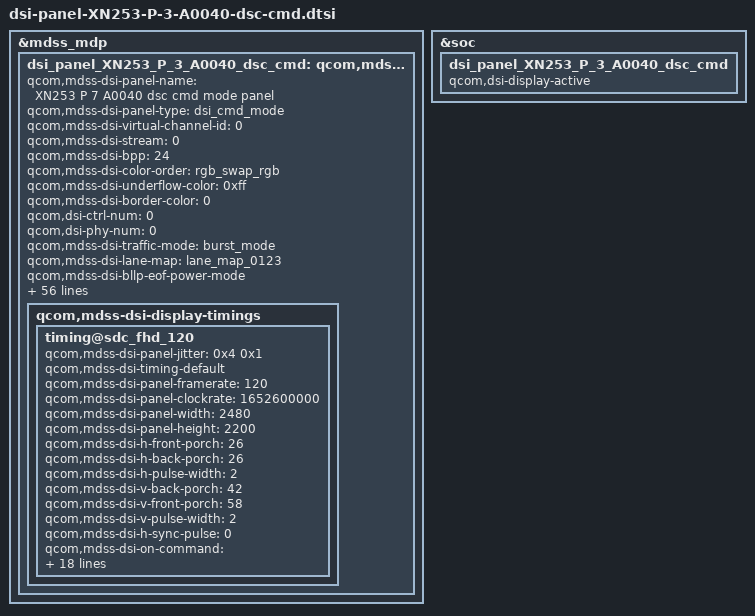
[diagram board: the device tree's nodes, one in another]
&mdss_mdp {
	dsi_panel_XN253_P_3_A0040_dsc_cmd: qcom,mdss_dsi_panel_XN253_P_3_A0040_dsc_cmd {
		qcom,mdss-dsi-panel-name = "XN253 P 7 A0040 dsc cmd mode panel";
		qcom,mdss-dsi-panel-type = "dsi_cmd_mode";
		qcom,mdss-dsi-virtual-channel-id = <0>;
		qcom,mdss-dsi-stream = <0>;
		qcom,mdss-dsi-bpp = <24>;
		qcom,mdss-dsi-color-order = "rgb_swap_rgb";
		qcom,mdss-dsi-underflow-color = <0xff>;
		qcom,mdss-dsi-border-color = <0>;
		qcom,dsi-ctrl-num = <0>;
		qcom,dsi-phy-num = <0>;
		qcom,mdss-dsi-traffic-mode = "burst_mode";
		qcom,mdss-dsi-lane-map = "lane_map_0123";
		qcom,mdss-dsi-bllp-eof-power-mode;
		qcom,mdss-dsi-bllp-power-mode;
		qcom,mdss-dsi-lane-0-state;
		qcom,mdss-dsi-lane-1-state;
		qcom,mdss-dsi-lane-2-state;
		qcom,mdss-dsi-lane-3-state;
		qcom,mdss-dsi-dma-trigger = "trigger_sw";
		qcom,mdss-dsi-dma-schedule-line = <1>;
		qcom,mdss-dsi-dma-schedule-window = <10>;
		qcom,mdss-dsi-mdp-trigger = "none";
		qcom,mdss-dsi-reset-sequence = <1 2>, <0 5>, <1 25>;
		qcom,mdss-dsi-te-pin-select = <1>;
		qcom,mdss-dsi-te-dcs-command = <1>;
		qcom,mdss-pan-physical-width-dimension = <71>;
		qcom,mdss-pan-physical-height-dimension = <157>;
		qcom,mdss-dsi-init-delay-us = <1000>;
		qcom,mdss-dsi-te-check-enable;
		qcom,mdss-dsi-te-using-te-pin;
		qcom,mdss-dsi-lp11-init;
		qcom,mdss-dsi-wr-mem-start = <0x2c>;
		qcom,mdss-dsi-wr-mem-continue = <0x3c>;
		qcom,mdss-dsi-panel-jitter = <0x4 0x1>;
		qcom,mdss-bl-high2bit;
		/* HDR Setting */
		qcom,mdss-dsi-panel-hdr-enabled;
		qcom,mdss-dsi-panel-hdr-color-primaries = <15635 16450 34000 16000 13250 34500 7500 3000>;
		//update for [MPC15]android.mediapc.cts.PerformanceClassTest#testDisplayHdr pass
		//qcom,mdss-dsi-panel-peak-brightness = <5400000>;
		qcom,mdss-dsi-panel-peak-brightness = <20000000>;
		qcom,mdss-dsi-panel-average-brightness = <2000000>;
		qcom,mdss-dsi-panel-blackness-level = <4000>;


		qcom,mdss-dsi-display-timings {
			timing@sdc_fhd_120 {
				//qcom,mdss-mdp-transfer-time-us = <6900>;
				qcom,mdss-dsi-panel-jitter = <0x4 0x1>;
				qcom,mdss-dsi-timing-default;
				qcom,mdss-dsi-panel-framerate = <120>;
				qcom,mdss-dsi-panel-clockrate = <1652600000>;
				qcom,mdss-dsi-panel-width = <2480>;
				qcom,mdss-dsi-panel-height = <2200>;

				qcom,mdss-dsi-h-front-porch = <26>;
				qcom,mdss-dsi-h-back-porch = <26>;
				qcom,mdss-dsi-h-pulse-width = <2>;
				qcom,mdss-dsi-v-back-porch = <42>;
				qcom,mdss-dsi-v-front-porch = <58>;
				qcom,mdss-dsi-v-pulse-width = <2>;
				qcom,mdss-dsi-h-sync-pulse = <0>;

				qcom,mdss-dsi-on-command = [
					39 00 00 00 00 00 06 F0 55 AA 52 08 00
					15 00 00 00 00 00 02 B5 80
					15 00 00 00 00 00 02 6F 02
					15 00 00 00 00 00 02 B5 3F
					15 00 00 00 00 00 02 6F 06
					15 00 00 00 00 00 02 B5 7F
					39 00 00 00 00 00 06 F0 55 AA 52 08 00
					15 00 00 00 00 00 02 6F CA
					15 00 00 00 00 00 02 D5 55
					15 00 00 00 00 00 02 6F 08
					15 00 00 00 00 00 02 D5 24
					15 00 00 00 00 00 02 6F 03
					15 00 00 00 00 00 02 B5 65
					39 00 00 00 00 00 03 D5 76 00
					15 00 00 00 00 00 02 6F 02
					15 00 00 00 00 00 02 D5 00
					15 00 00 00 00 00 02 6F 4E
					15 00 00 00 00 00 02 D5 00
					15 00 00 00 00 00 02 6F 4F
					39 00 00 00 00 00 04 D5 00 00 00
					15 00 00 00 00 00 02 6F 52
					39 00 00 00 00 00 04 D5 00 00 00
					15 00 00 00 00 00 02 6F AA
					15 00 00 00 00 00 02 D5 00
					15 00 00 00 00 00 02 6F AB
					39 00 00 00 00 00 04 D5 00 00 00
					15 00 00 00 00 00 02 6F AE
					39 00 00 00 00 00 04 D5 00 00 00
					15 00 00 00 00 00 02 6F B8
					15 00 00 00 00 00 02 D5 00
					15 00 00 00 00 00 02 6F B9
					39 00 00 00 00 00 04 D5 00 00 00
					15 00 00 00 00 00 02 6F BC
					39 00 00 00 00 00 04 D5 00 00 00
					15 00 00 00 00 00 02 6F 5C
					15 00 00 00 00 00 02 D5 03
					15 00 00 00 00 00 02 6F 5D
					39 00 00 00 00 00 07 D5 04 05 07 00 00 00
					15 00 00 00 00 00 02 6F 63
					39 00 00 00 00 00 07 D5 1D 30 59 00 00 00
					15 00 00 00 00 00 02 6F 69
					15 00 00 00 00 00 02 D5 01
					15 00 00 00 00 00 02 6F 6A
					39 00 00 00 00 00 07 D5 07 00 00 00 00 00
					15 00 00 00 00 00 02 6F 70
					39 00 00 00 00 00 07 D5 58 00 00 00 00 00
					15 00 00 00 00 00 02 6F BF
					15 00 00 00 00 00 02 D5 00
					15 00 00 00 00 00 02 6F C0
					39 00 00 00 00 00 04 D5 00 00 00
					15 00 00 00 00 00 02 6F C3
					39 00 00 00 00 00 04 D5 00 00 00
					15 00 00 00 00 00 02 6F B1
					15 00 00 00 00 00 02 D5 00
					15 00 00 00 00 00 02 6F B2
					39 00 00 00 00 00 04 D5 00 00 00
					15 00 00 00 00 00 02 6F B5
					39 00 00 00 00 00 04 D5 00 00 00
					15 00 00 00 00 00 02 6F 55
					15 00 00 00 00 00 02 D5 00
					15 00 00 00 00 00 02 6F 56
					39 00 00 00 00 00 04 D5 00 00 00
					15 00 00 00 00 00 02 6F 59
					39 00 00 00 00 00 04 D5 00 00 00
					15 00 00 00 00 00 02 6F 76
					15 00 00 00 00 00 02 D5 02
					15 00 00 00 00 00 02 6F 77
					39 00 00 00 00 00 07 D5 04 05 00 00 00 00
					15 00 00 00 00 00 02 6F 7D
					39 00 00 00 00 00 07 D5 1D 0E 00 00 00 00
					15 00 00 00 00 00 02 6F 90
					15 00 00 00 00 00 02 D5 01
					15 00 00 00 00 00 02 6F 91
					39 00 00 00 00 00 07 D5 07 00 00 00 00 00
					15 00 00 00 00 00 02 6F 97
					39 00 00 00 00 00 07 D5 40 00 00 00 00 00
					15 00 00 00 00 00 02 6F 9D
					15 00 00 00 00 00 02 D5 01
					15 00 00 00 00 00 02 6F 9E
					39 00 00 00 00 00 07 D5 07 00 00 00 00 00
					15 00 00 00 00 00 02 6F A4
					39 00 00 00 00 00 07 D5 59 00 00 00 00 00
					15 00 00 00 00 00 02 6F 83
					15 00 00 00 00 00 02 D5 02
					15 00 00 00 00 00 02 6F 84
					39 00 00 00 00 00 07 D5 04 05 00 00 00 00
					15 00 00 00 00 00 02 6F 8A
					39 00 00 00 00 00 07 D5 1D 30 00 00 00 00
					15 00 00 00 00 00 02 6F D1
					15 00 00 00 00 00 02 D5 62
					39 00 00 00 00 00 06 F0 55 AA 52 08 00
					15 00 00 00 00 00 02 6F 02
					15 00 00 00 00 00 02 C0 08
					15 00 00 00 00 00 02 6F 11
					39 00 00 00 00 00 06 B5 30 30 30 30 30
					39 00 00 00 00 00 06 F0 55 AA 52 08 00
					39 00 00 00 00 00 07 C8 0D 0D 0D 0D 08 08
					15 00 00 00 00 00 02 6F 0B
					39 00 00 00 00 00 09 C8 0C 0C 04 04 0C 0C 08 08
					39 00 00 00 00 00 06 F0 55 AA 52 08 01
					15 00 00 00 00 00 02 6F 03
					15 00 00 00 00 00 02 D9 40
					15 00 00 00 00 00 02 6F 23
					39 00 00 00 00 00 04 D9 C1 C9 12
					39 00 00 00 00 00 06 F0 55 AA 52 08 00
					15 00 00 00 00 00 02 6F 1C
					39 00 00 00 00 00 05 B2 0F FF 0F FF
					15 00 00 00 00 00 02 6F CD
					39 00 00 00 00 00 05 B2 0F FF 0F FF
					15 00 00 00 00 00 02 6F D6
					15 00 00 00 00 00 02 B2 02
					39 00 00 00 00 00 06 F0 55 AA 52 08 01
					15 00 00 00 00 00 02 6F 03
					15 00 00 00 00 00 02 C7 00
					15 00 00 00 00 00 02 6F 05
					15 00 00 00 00 00 02 C7 37
					15 00 00 00 00 00 02 6F 09
					15 00 00 00 00 00 02 C7 24
					39 00 00 00 00 00 06 F0 55 AA 52 08 05
					39 00 00 00 00 00 06 CB 33 33 33 33 33
					15 00 00 00 00 00 02 6F 00
					39 00 00 00 00 00 09 D7 33 33 33 33 33 33 FF FF
					39 00 00 00 00 00 06 F0 55 AA 52 08 00
					15 00 00 00 00 00 02 6F 2C
					15 00 00 00 00 00 02 CB 43
					39 00 00 00 00 00 05 FF AA 55 A5 80
					15 00 00 00 00 00 02 6F 29
					39 00 00 00 00 00 03 F8 0E 36
					15 00 00 00 00 00 02 6F 0D
					39 00 00 00 00 00 03 F8 01 7F
					39 00 00 00 00 00 05 FF AA 55 A5 81
					15 00 00 00 00 00 02 6F 02
					15 00 00 00 00 00 02 F9 04
					15 00 00 00 00 00 02 6F 0E
					15 00 00 00 00 00 02 F5 2B
					39 00 00 00 00 00 06 F0 55 AA 52 08 03
					39 00 00 00 00 00 04 C8 01 FF FB
					39 00 00 00 00 00 05 FF AA 55 A5 80
					15 00 00 00 00 00 02 6F 22
					15 00 00 00 00 00 02 FE 04
					39 00 00 00 00 00 06 F0 55 AA 52 08 04
					15 00 00 00 00 00 02 6F 01
					39 00 00 00 00 00 04 B5 00 14 3B
					39 00 00 00 00 00 05 FF AA 55 A5 82
					15 00 00 00 00 00 02 6F 11
					15 00 00 00 00 00 02 F8 0F
					39 00 00 00 00 00 06 F0 55 AA 52 00 00
					39 00 00 00 00 00 05 FF AA 55 A5 00
					15 00 00 00 00 00 02 6F 26
					39 00 00 00 00 00 08 44 02 98 02 98 68 03 00
					15 00 00 00 00 00 02 6F 4F
					39 00 00 00 00 00 03 44 00 00
					15 00 00 00 00 00 02 6F 63
					15 00 00 00 00 00 02 44 66
					15 00 00 00 00 00 02 6F 14
					15 00 00 00 00 00 02 35 60
					15 00 00 00 00 00 02 6F 04
					15 00 00 00 00 00 02 35 00
					15 00 00 00 00 00 02 6F 2D
					39 00 00 00 00 00 08 44 02 98 02 98 68 03 00
					15 00 00 00 00 00 02 6F 54
					39 00 00 00 00 00 03 44 00 00
					15 00 00 00 00 00 02 6F 63
					15 00 00 00 00 00 02 44 66
					15 00 00 00 00 00 02 6F 15
					15 00 00 00 00 00 02 35 E0
					15 00 00 00 00 00 02 6F 06
					15 00 00 00 00 00 02 6D 48
					05 00 00 00 00 00 01 35
					39 00 00 00 00 00 03 51 01 FF
					15 00 00 00 00 00 02 53 20
					39 00 00 00 00 00 03 5F 00 00
					15 00 00 00 00 00 02 A2 01
					39 00 00 00 00 00 05 2A 00 00 09 AF
					39 00 00 00 00 00 05 2B 00 00 08 97
					39 00 00 00 00 00 03 90 03 43
					39 00 00 00 00 00 13 91 89 28 00 14 C2 00 03 6D 02 A7 00 11 05 0E 02 2F 10 D0
					15 00 00 00 00 00 02 2F 01
					05 00 00 00 78 00 01 11

					39 00 00 00 00 00 06 F0 55 AA 52 08 01
					15 00 00 00 00 00 02 6F 24
					39 00 00 00 00 00 14 E5 04 C0 0C 10 10 0C 0C C0 0C 10 0C 0C 0C C0 08 10 0C 0C 0C
					05 00 00 00 00 00 01 29
				];
				qcom,mdss-dsi-off-command = [
					15 01 00 00 0A 00 02 28 00
					15 01 00 00 41 00 02 10 00
				];
				qcom,mdss-dsi-on-command-state = "dsi_lp_mode";
				qcom,mdss-dsi-off-command-state = "dsi_lp_mode";

				qcom,compression-mode = "dsc";
				qcom,mdss-dsc-version = <0x11>;
				qcom,mdss-dsc-encoders = <1>;
				qcom,mdss-dsc-slice-height = <20>;
				qcom,mdss-dsc-slice-width = <1240>;
				qcom,mdss-dsc-slice-per-pkt = <2>;
				qcom,mdss-dsc-bit-per-component = <8>;
				qcom,mdss-dsc-bit-per-pixel = <8>;
				qcom,mdss-dsc-block-prediction-enable;
			};
		};
	};
};

&soc {
	dsi_panel_XN253_P_3_A0040_dsc_cmd {
		qcom,dsi-display-active;
	};
};

&dsi_panel_XN253_P_3_A0040_dsc_cmd {
	qcom,panel-supply-entries = <&oplus_dsi_panel_custom_pwr_supply>;
	qcom,platform-te-gpio = <&tlmm 86 0>;
	qcom,platform-reset-gpio = <&tlmm 171 0>;
	/* DVDDP 1p3 enable */
	oplus,panel-gpio1 = <&pmh0101_gpios 4 0>;
	/* PMIC SGM3820 enable */
	oplus,panel-gpio2 = <&pmh0110_i_gpios 11 0>;

	oplus,panel-reset-position = <0x02>;
	oplus,panel-power-on-sequence = "1", "vddio", "3", "vdd", "3", "gpio1",  "vci", "5", "gpio2", "3";
	oplus,panel-power-off-sequence = "1", "gpio2", "3", "vci", "3", "gpio1", "0", "vdd", "3", "vddio", "1";


	/* BRIGHTNESS CONFIG */
	qcom,mdss-dsi-bl-pmic-control-type = "bl_ctrl_dcs";
	qcom,bl-update-flag = "delay_until_first_frame";
	qcom,mdss-dsi-bl-inverted-dbv;
	qcom,mdss-dsi-bl-min-level = <1>;
	qcom,mdss-dsi-bl-max-level = <4094>;
	qcom,mdss-brightness-max-level = <4094>;
	oplus,dsi-bl-normal-max-level = <3515>;
	oplus,dsi-brightness-normal-max-level = <3515>;
	oplus,dsi-dc-backlight-threshold = <1960>;
	oplus,dsi-brightness-default-level = <1638>;


	/* FACTORY CONFIG */
	oplus,mdss-dsi-vendor-name = "A0040";
	oplus,mdss-dsi-manufacture = "P_3";



	qcom,ulps-enabled;
	qcom,dsi-select-clocks = "pll_byte_clk0", "pll_dsi_clk0";

	qcom,mdss-dsi-display-timings {
		timing@sdc_fhd_120 { /* FHD+ 120hz 1112.6Mbps */
			qcom,mdss-dsi-panel-phy-timings = [00 38 0E 0E 20 1D 0E 0E 0D 02 04 00 2C 13];
			qcom,display-topology = <1 1 1>,<2 2 1>;
			qcom,default-topology-index = <1>;
		};
	};
};


